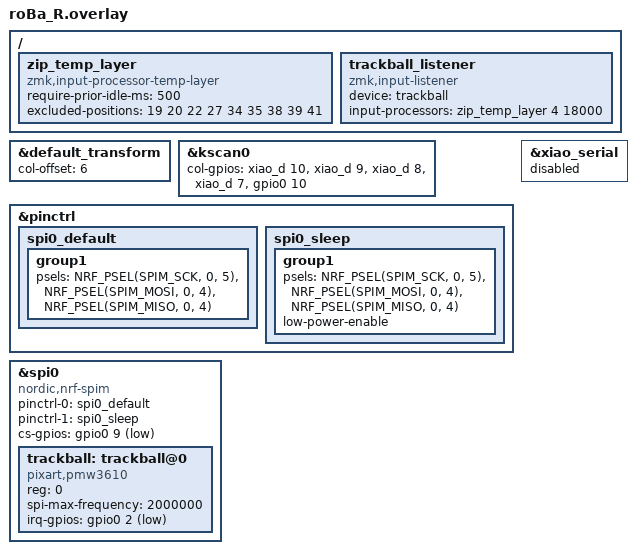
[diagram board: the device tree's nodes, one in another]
#include <input/processors.dtsi>
#include "roBa.dtsi"

&default_transform {
    col-offset = <6>;
};

&kscan0 {
        col-gpios
            = <&xiao_d 10 GPIO_ACTIVE_HIGH>
            , <&xiao_d 9 GPIO_ACTIVE_HIGH>
            , <&xiao_d 8 GPIO_ACTIVE_HIGH>
            , <&xiao_d 7 GPIO_ACTIVE_HIGH>
            , <&gpio0 10 GPIO_ACTIVE_HIGH>
            ;
};
/ {
// AutoMouseLayer改修(20251005)
    /omit-if-no-ref/ zip_temp_layer: zip_temp_layer {
        compatible = "zmk,input-processor-temp-layer";
        #input-processor-cells = <2>;
        require-prior-idle-ms = <500>; //キー入力後のALM非発動時間
        excluded-positions = < //AML離脱キーの除外定義
            19 //左クリック
            20 //
            22 //Shift
            27
            //31 //左クリック
            //33 //右クリック
            34 //Ctrl
            35 //Alt
            //36 Tab
            //37 レイヤー遷移キーでAML解除
            38
            39
            //40 レイヤー遷移キーでAML解除
            41
        >;
    };

    trackball_listener {
        status = "okay";
        compatible = "zmk,input-listener";
        device = <&trackball>;
        // AutoMouseLayer改修(20251005)
        input-processors = <&zip_temp_layer 4 18000>;//カーソル移動後のAML滞在時間
    };
};

&pinctrl {
    spi0_default: spi0_default {
        group1 {
            psels = <NRF_PSEL(SPIM_SCK, 0, 5)>,
                <NRF_PSEL(SPIM_MOSI, 0, 4)>,
                <NRF_PSEL(SPIM_MISO, 0, 4)>;
        };
    };

    spi0_sleep: spi0_sleep {
        group1 {
            psels = <NRF_PSEL(SPIM_SCK, 0, 5)>,
                <NRF_PSEL(SPIM_MOSI, 0, 4)>,
                <NRF_PSEL(SPIM_MISO, 0, 4)>;
            low-power-enable;
        };
    };
};

&xiao_serial { status = "disabled"; };

&spi0 {
    status = "okay";
    compatible = "nordic,nrf-spim";
    pinctrl-0 = <&spi0_default>;
    pinctrl-1 = <&spi0_sleep>;
    pinctrl-names = "default", "sleep";
    cs-gpios = <&gpio0 9 GPIO_ACTIVE_LOW>;

    trackball: trackball@0 {
        status = "okay";
        compatible = "pixart,pmw3610";
        reg = <0>;
        spi-max-frequency = <2000000>;
        irq-gpios = <&gpio0 2 (GPIO_ACTIVE_LOW | GPIO_PULL_UP)>;
    };
};
